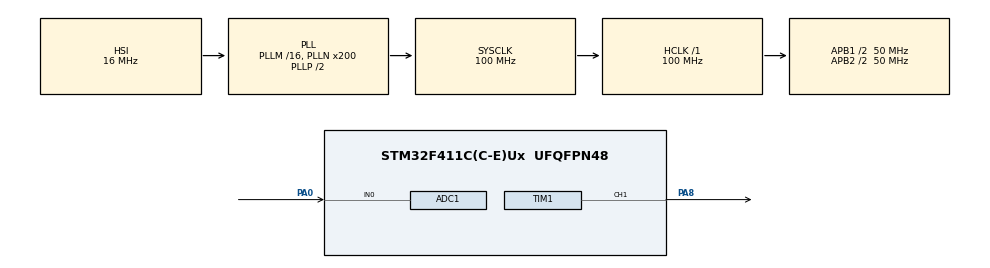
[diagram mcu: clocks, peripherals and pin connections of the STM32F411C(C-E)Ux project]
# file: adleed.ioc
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ADC1.Channel-0\#ChannelRegularConversion=ADC_CHANNEL_0
ADC1.NbrOfConversionFlag=1
ADC1.Rank-0\#ChannelRegularConversion=1
ADC1.Resolution=ADC_RESOLUTION_8B
ADC1.SamplingTime-0\#ChannelRegularConversion=ADC_SAMPLETIME_3CYCLES
ADC1.master=1
Dma.Request0=TIM1_CH1
Dma.TIM1_CH1.0.Direction=DMA_MEMORY_TO_PERIPH
Dma.TIM1_CH1.0.FIFOMode=DMA_FIFOMODE_DISABLE
Dma.TIM1_CH1.0.Instance=DMA2_Stream1
Dma.TIM1_CH1.0.MemDataAlignment=DMA_MDATAALIGN_HALFWORD
Dma.TIM1_CH1.0.MemInc=DMA_MINC_ENABLE
Dma.TIM1_CH1.0.Mode=DMA_NORMAL
Dma.TIM1_CH1.0.PeriphDataAlignment=DMA_PDATAALIGN_HALFWORD
Dma.TIM1_CH1.0.PeriphInc=DMA_PINC_DISABLE
Dma.TIM1_CH1.0.Priority=DMA_PRIORITY_LOW
Mcu.Family=STM32F4
Mcu.Name=STM32F411C(C-E)Ux
Mcu.Package=UFQFPN48
NVIC.DMA2_Stream1_IRQn=true\:0\:0\:false\:false\:true\:false\:true\:true
NVIC.PriorityGroup=NVIC_PRIORITYGROUP_4
PA0-WKUP.Signal=ADCx_IN0
PA8.Signal=S_TIM1_CH1
ProjectManager.HeapSize=0x200
ProjectManager.StackSize=0x400
ProjectManager.TargetToolchain=STM32CubeIDE
RCC.48MHZClocksFreq_Value=50000000
RCC.AHBFreq_Value=100000000
RCC.APB1CLKDivider=RCC_HCLK_DIV2
RCC.APB1Freq_Value=50000000
RCC.APB1TimFreq_Value=100000000
RCC.APB2CLKDivider=RCC_HCLK_DIV2
RCC.APB2Freq_Value=50000000
RCC.APB2TimFreq_Value=100000000
RCC.CortexFreq_Value=100000000
RCC.HCLKFreq_Value=100000000
RCC.HSE_VALUE=25000000
RCC.HSI_VALUE=16000000
RCC.LSE_VALUE=32768
RCC.PLLN=200
RCC.SYSCLKFreq_VALUE=100000000
RCC.SYSCLKSource=RCC_SYSCLKSOURCE_PLLCLK
RCC.VCOOutputFreq_Value=200000000
SH.ADCx_IN0.0=ADC1_IN0,IN0
SH.S_TIM1_CH1.0=TIM1_CH1,PWM Generation1 CH1
TIM1.AutoReloadPreload=TIM_AUTORELOAD_PRELOAD_ENABLE
TIM1.Channel-PWM\ Generation1\ CH1=TIM_CHANNEL_1
TIM1.Period=124
TIM1.Pulse-PWM\ Generation1\ CH1=40
board=custom

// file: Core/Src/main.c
/* USER CODE BEGIN Header */
/**
  ******************************************************************************
  * @file           : main.c
  * @brief          : Main program body
  ******************************************************************************
  * @attention
  *
  * Copyright (c) 2026 STMicroelectronics.
  * All rights reserved.
  *
  * This software is licensed under terms that can be found in the LICENSE file
  * in the root directory of this software component.
  * If no LICENSE file comes with this software, it is provided AS-IS.
  *
  ******************************************************************************
  */
/* USER CODE END Header */
#include "main.h"

/* USER CODE BEGIN PD */
#define NUM_LEDS 12

#define WS2812_RESET_BITS 40
/* USER CODE END PD */

ADC_HandleTypeDef hadc1;

TIM_HandleTypeDef htim1;
DMA_HandleTypeDef hdma_tim1_ch1;

/* USER CODE BEGIN PV */
uint8_t led_data[NUM_LEDS][3];

uint16_t pwm_buffer[1 + (NUM_LEDS * 24) + WS2812_RESET_BITS];

uint16_t speed = 1000;

volatile uint8_t _dma_done = 0;
/* USER CODE END PV */

void SystemClock_Config(void);
static void MX_GPIO_Init(void);
static void MX_DMA_Init(void);
static void MX_TIM1_Init(void);
static void MX_ADC1_Init(void);
/* USER CODE BEGIN PFP */
void WS2812_SetPixel(uint16_t index, uint8_t r, uint8_t g, uint8_t b);
void WS2812_Show();

void HAL_TIM_PWM_PulseFinishedCallback(TIM_HandleTypeDef *htim);
/* USER CODE END PFP */

int main(void)
{

  /* MCU Configuration--------------------------------------------------------*/

  /* Reset of all peripherals, Initializes the Flash interface and the Systick. */
  HAL_Init();

  /* Configure the system clock */
  SystemClock_Config();

  /* Initialize all configured peripherals */
  MX_GPIO_Init();
  MX_DMA_Init();
  MX_TIM1_Init();
  MX_ADC1_Init();
  /* USER CODE BEGIN 2 */
//  WS2812_SetPixel(0, 255, 0, 0);
//  WS2812_SetPixel(2, 0, 0, 255);
//  WS2812_SetPixel(4, 0, 255, 255);
//  WS2812_SetPixel(6, 255, 255, 255);
//  WS2812_Show();
  int rotate = 0;
  /* USER CODE END 2 */

  /* Infinite loop */
  /* USER CODE BEGIN WHILE */
  while (1)
  {
	  HAL_ADC_Start(&hadc1);

	  if (HAL_ADC_PollForConversion(&hadc1, 100) == HAL_OK) {
		  speed = (255 - HAL_ADC_GetValue(&hadc1))/20 + 10;
		  WS2812_SetPixel(rotate + 6 >= NUM_LEDS ? rotate - 6 : rotate + 6, 0, 0, 0);
		  WS2812_SetPixel(rotate, HAL_ADC_GetValue(&hadc1), 0, 0);
		  WS2812_Show();
		  HAL_Delay(speed);
		  rotate++;
		  if (rotate >= NUM_LEDS) rotate = 0;
	  }
	  else
	  {
		  for (int i = 0; i < NUM_LEDS; i++){
		  	WS2812_SetPixel(i, 255, 0, 0);
		  	WS2812_Show();
		  }
		  HAL_Delay(speed);
		  for (int i = 0; i < NUM_LEDS; i++){
		  	WS2812_SetPixel(i, 0, 0, 0);
		  	WS2812_Show();
		  }
	  }

	  HAL_ADC_Stop(&hadc1);
    /* USER CODE END WHILE */

  }
}

void SystemClock_Config(void)
{
  RCC_OscInitTypeDef RCC_OscInitStruct = {0};
  RCC_ClkInitTypeDef RCC_ClkInitStruct = {0};

  /** Configure the main internal regulator output voltage
  */
  __HAL_RCC_PWR_CLK_ENABLE();
  __HAL_PWR_VOLTAGESCALING_CONFIG(PWR_REGULATOR_VOLTAGE_SCALE1);

  /** Initializes the RCC Oscillators according to the specified parameters
  * in the RCC_OscInitTypeDef structure.
  */
  RCC_OscInitStruct.OscillatorType = RCC_OSCILLATORTYPE_HSI;
  RCC_OscInitStruct.HSIState = RCC_HSI_ON;
  RCC_OscInitStruct.HSICalibrationValue = RCC_HSICALIBRATION_DEFAULT;
  RCC_OscInitStruct.PLL.PLLState = RCC_PLL_ON;
  RCC_OscInitStruct.PLL.PLLSource = RCC_PLLSOURCE_HSI;
  RCC_OscInitStruct.PLL.PLLM = 16;
  RCC_OscInitStruct.PLL.PLLN = 200;
  RCC_OscInitStruct.PLL.PLLP = RCC_PLLP_DIV2;
  RCC_OscInitStruct.PLL.PLLQ = 4;
  if (HAL_RCC_OscConfig(&RCC_OscInitStruct) != HAL_OK)
  {
    Error_Handler();
  }

  /** Initializes the CPU, AHB and APB buses clocks
  */
  RCC_ClkInitStruct.ClockType = RCC_CLOCKTYPE_HCLK|RCC_CLOCKTYPE_SYSCLK
                              |RCC_CLOCKTYPE_PCLK1|RCC_CLOCKTYPE_PCLK2;
  RCC_ClkInitStruct.SYSCLKSource = RCC_SYSCLKSOURCE_PLLCLK;
  RCC_ClkInitStruct.AHBCLKDivider = RCC_SYSCLK_DIV1;
  RCC_ClkInitStruct.APB1CLKDivider = RCC_HCLK_DIV2;
  RCC_ClkInitStruct.APB2CLKDivider = RCC_HCLK_DIV2;

  if (HAL_RCC_ClockConfig(&RCC_ClkInitStruct, FLASH_LATENCY_3) != HAL_OK)
  {
    Error_Handler();
  }
}

static void MX_ADC1_Init(void)
{

  ADC_ChannelConfTypeDef sConfig = {0};

  /** Configure the global features of the ADC (Clock, Resolution, Data Alignment and number of conversion)
  */
  hadc1.Instance = ADC1;
  hadc1.Init.ClockPrescaler = ADC_CLOCK_SYNC_PCLK_DIV2;
  hadc1.Init.Resolution = ADC_RESOLUTION_8B;
  hadc1.Init.ScanConvMode = DISABLE;
  hadc1.Init.ContinuousConvMode = DISABLE;
  hadc1.Init.DiscontinuousConvMode = DISABLE;
  hadc1.Init.ExternalTrigConvEdge = ADC_EXTERNALTRIGCONVEDGE_NONE;
  hadc1.Init.ExternalTrigConv = ADC_SOFTWARE_START;
  hadc1.Init.DataAlign = ADC_DATAALIGN_RIGHT;
  hadc1.Init.NbrOfConversion = 1;
  hadc1.Init.DMAContinuousRequests = DISABLE;
  hadc1.Init.EOCSelection = ADC_EOC_SINGLE_CONV;
  if (HAL_ADC_Init(&hadc1) != HAL_OK)
  {
    Error_Handler();
  }

  /** Configure for the selected ADC regular channel its corresponding rank in the sequencer and its sample time.
  */
  sConfig.Channel = ADC_CHANNEL_0;
  sConfig.Rank = 1;
  sConfig.SamplingTime = ADC_SAMPLETIME_3CYCLES;
  if (HAL_ADC_ConfigChannel(&hadc1, &sConfig) != HAL_OK)
  {
    Error_Handler();
  }

}

static void MX_TIM1_Init(void)
{

  TIM_MasterConfigTypeDef sMasterConfig = {0};
  TIM_OC_InitTypeDef sConfigOC = {0};
  TIM_BreakDeadTimeConfigTypeDef sBreakDeadTimeConfig = {0};

  htim1.Instance = TIM1;
  htim1.Init.Prescaler = 0;
  htim1.Init.CounterMode = TIM_COUNTERMODE_UP;
  htim1.Init.Period = 124;
  htim1.Init.ClockDivision = TIM_CLOCKDIVISION_DIV1;
  htim1.Init.RepetitionCounter = 0;
  htim1.Init.AutoReloadPreload = TIM_AUTORELOAD_PRELOAD_ENABLE;
  if (HAL_TIM_PWM_Init(&htim1) != HAL_OK)
  {
    Error_Handler();
  }
  sMasterConfig.MasterOutputTrigger = TIM_TRGO_RESET;
  sMasterConfig.MasterSlaveMode = TIM_MASTERSLAVEMODE_DISABLE;
  if (HAL_TIMEx_MasterConfigSynchronization(&htim1, &sMasterConfig) != HAL_OK)
  {
    Error_Handler();
  }
  sConfigOC.OCMode = TIM_OCMODE_PWM1;
  sConfigOC.Pulse = 40;
  sConfigOC.OCPolarity = TIM_OCPOLARITY_HIGH;
  sConfigOC.OCNPolarity = TIM_OCNPOLARITY_HIGH;
  sConfigOC.OCFastMode = TIM_OCFAST_DISABLE;
  sConfigOC.OCIdleState = TIM_OCIDLESTATE_RESET;
  sConfigOC.OCNIdleState = TIM_OCNIDLESTATE_RESET;
  if (HAL_TIM_PWM_ConfigChannel(&htim1, &sConfigOC, TIM_CHANNEL_1) != HAL_OK)
  {
    Error_Handler();
  }
  sBreakDeadTimeConfig.OffStateRunMode = TIM_OSSR_DISABLE;
  sBreakDeadTimeConfig.OffStateIDLEMode = TIM_OSSI_DISABLE;
  sBreakDeadTimeConfig.LockLevel = TIM_LOCKLEVEL_OFF;
  sBreakDeadTimeConfig.DeadTime = 0;
  sBreakDeadTimeConfig.BreakState = TIM_BREAK_DISABLE;
  sBreakDeadTimeConfig.BreakPolarity = TIM_BREAKPOLARITY_HIGH;
  sBreakDeadTimeConfig.AutomaticOutput = TIM_AUTOMATICOUTPUT_DISABLE;
  if (HAL_TIMEx_ConfigBreakDeadTime(&htim1, &sBreakDeadTimeConfig) != HAL_OK)
  {
    Error_Handler();
  }
  HAL_TIM_MspPostInit(&htim1);

}

static void MX_DMA_Init(void)
{

  /* DMA controller clock enable */
  __HAL_RCC_DMA2_CLK_ENABLE();

  /* DMA interrupt init */
  /* DMA2_Stream1_IRQn interrupt configuration */
  HAL_NVIC_SetPriority(DMA2_Stream1_IRQn, 0, 0);
  HAL_NVIC_EnableIRQ(DMA2_Stream1_IRQn);

}

static void MX_GPIO_Init(void)
{

  /* GPIO Ports Clock Enable */
  __HAL_RCC_GPIOA_CLK_ENABLE();

}

/* USER CODE BEGIN 4 */
void WS2812_SetPixel(uint16_t index, uint8_t r, uint8_t g, uint8_t b){
	led_data[index][0] = g;
	led_data[index][1] = r;
	led_data[index][2] = b;
}

void WS2812_Show(){
	// Reset the blocking flag
	_dma_done = 0;

	// Encode led_data[] into pwm_buffer[]
	uint16_t pwm_index = 0;

	// We will be beginning each packet with 0 due to some bug in DMA that doubles the length of the first bit
	pwm_buffer[pwm_index++] = 0;
	for (int index = 0; index < NUM_LEDS; index++){
		for(int colorIndex = 0; colorIndex < 3; colorIndex++){
			for(int bitIndex = 0; bitIndex < 8; bitIndex++){
				if (led_data[index][colorIndex] & (0x80 >> bitIndex)){
					pwm_buffer[pwm_index++] = 80;
				} else {
					pwm_buffer[pwm_index++] = 40;
				}
			}
		}
	}

	//Append reset zeroes
	for (int index = 0; index < WS2812_RESET_BITS; index++){
		pwm_buffer[pwm_index++] = 0;
	}

	// Start TIM1 DMA
	HAL_TIM_PWM_Start_DMA(&htim1, TIM_CHANNEL_1, (uint32_t *)pwm_buffer, NUM_LEDS * 24 + WS2812_RESET_BITS);

	// Wait until it ends to not mess up things.
	while (!_dma_done){}
}

void HAL_TIM_PWM_PulseFinishedCallback(TIM_HandleTypeDef *htim){
	if (htim->Instance == TIM1){
		_dma_done = 1;
	}
}

/* USER CODE END 4 */

void Error_Handler(void)
{
  __disable_irq();
  while (1)
  {
  }
}
